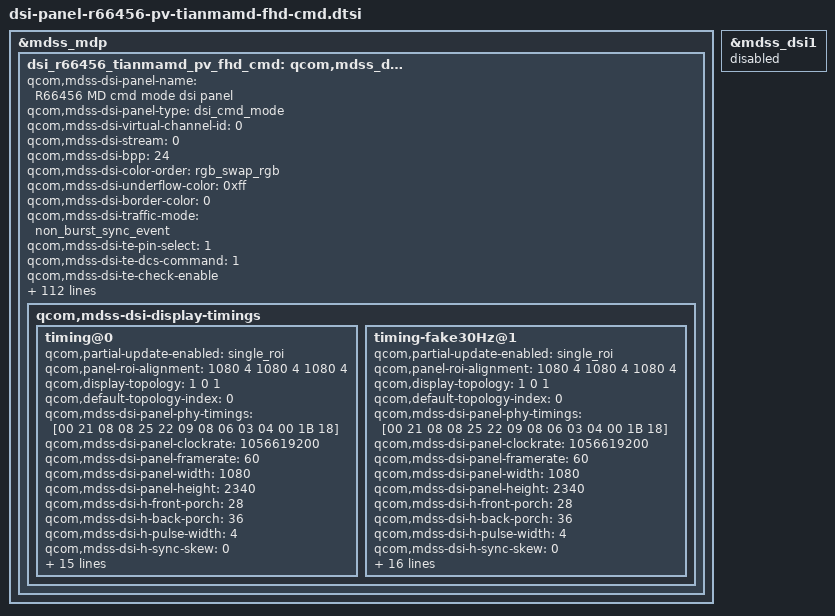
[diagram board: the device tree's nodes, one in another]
/* Copyright (c) 2014, Code Aurora Forum. All rights reserved.
 *
 * This program is free software; you can redistribute it and/or modify
 * it under the terms of the GNU General Public License version 2 and
 * only version 2 as published by the Free Software Foundation.
 *
 * This program is distributed in the hope that it will be useful,
 * but WITHOUT ANY WARRANTY; without even the implied warranty of
 * MERCHANTABILITY or FITNESS FOR A PARTICULAR PURPOSE.  See the
 * GNU General Public License for more details.
 */

&mdss_mdp {
    dsi_r66456_tianmamd_pv_fhd_cmd: qcom,mdss_dsi_r66456_tianmamd_pv_fhd_cmd {
		qcom,mdss-dsi-panel-name = "R66456 MD cmd mode dsi panel";
		qcom,mdss-dsi-panel-type = "dsi_cmd_mode";
		qcom,mdss-dsi-virtual-channel-id = <0>;
		qcom,mdss-dsi-stream = <0>;
		qcom,mdss-dsi-bpp = <24>;
		qcom,mdss-dsi-color-order = "rgb_swap_rgb";
		qcom,mdss-dsi-underflow-color = <0xff>;
		qcom,mdss-dsi-border-color = <0>;
		qcom,mdss-dsi-traffic-mode = "non_burst_sync_event";
		qcom,mdss-dsi-te-pin-select = <1>;
		qcom,mdss-dsi-te-dcs-command = <1>;
		qcom,mdss-dsi-te-check-enable;
		qcom,mdss-dsi-te-using-te-pin;
		qcom,mdss-dsi-lane-map = "lane_map_0123";
		qcom,mdss-dsi-bllp-eof-power-mode;
		qcom,mdss-dsi-bllp-power-mode;
		qcom,mdss-dsi-lane-0-state;
		qcom,mdss-dsi-lane-1-state;
		qcom,mdss-dsi-lane-2-state;
		qcom,mdss-dsi-lane-3-state;
		qcom,mdss-dsi-reset-sequence = <1 10>, <0 2>, <1 10>;
		qcom,mdss-dsi-dma-trigger = "trigger_sw";
		qcom,mdss-dsi-mdp-trigger = "none";
		qcom,mdss-dsi-wr-mem-start = <0x2c>;
		qcom,mdss-dsi-wr-mem-continue = <0x3c>;
		qcom,mdss-dsi-lp11-init;
		qcom,mdss-dsi-tx-eot-append;
		qcom,ulps-enabled;
		qcom,mdss-dsi-panel-hdr-enabled;
		qcom,mdss-dsi-panel-hdr-color-primaries = <14880 15935 32435 16555 14945 30910 7790 3415>;
		qcom,mdss-dsi-panel-peak-brightness = <5643000>;
		qcom,mdss-dsi-panel-blackness-level = <6134>;
		qcom,esd-check-enabled;
		qcom,mdss-dsi-panel-status-check-mode = "te_signal_check";

		lge,blmap = <
			0
			32 32 32 32 32 32 32 32 32 32 33 34 35 35 36 37 38 39 40 40
			41 42 43 44 45 46 46 47 48 49 50 51 51 52 53 54 57 59 62 65
			67 70 72 75 78 80 83 86 88 91 94 96 99 102 104 107 109 112 115 117
			120 126 131 137 143 148 154 160 165 171 177 182 188 194 199 205 211 216 222 228
			233 241 248 255 256 263 271 278 285 293 300 307 314 322 329 336 344 351 358 366
			373 380 387 395 402 409 417 424 434 443 453 462 472 481 491 500 510 519 529 538
			548 558 567 577 586 596 605 615 624 634 643 653 662 672 685 699 712 726 739 753
			766 776 789 802 816 829 843 856 870 883 897 910 923 937 950 964 977 991 1008 1023
			1026 1028 1030 1032 1034 1038 1042 1046 1055 1059 1060 1061 1075 1098 1131 1166 1203 1242 1283 1323
			1345 1361 1376 1393 1410 1427 1444 1461 1478 1495 1512 1529 1546 1563 1580 1597 1614 1631 1648 1665
			1682 1699 1716 1733 1750 1767 1784 1803 1822 1842 1861 1880 1899 1918 1938 1957 1976 1995 2014 2034
			2053 2072 2091 2110 2130 2149 2168 2187 2206 2226 2245 2264 2289 2315 2340 2366 2391 2416 2442 2467
			2493 2518 2543 2569 2594 2619 2645 2670 2696 2721 2746 2772 2797 2823 2848 2850 2851 2853 2855 2856
			2858 2860 2861 2863 2865 2866 2868 2870 2871 2873 2875 2877 2878 2880 2882 2883 2885 2887 2888 2890
			2892 2893 2895 2897 2898 2900 2904 2908 2911 2915 2919 2923 2926 2930 2938 2945 2953 2960 2968 2975
			2983 2990 2999 3009 3018 3028 3037 3047 3056 3066 3075 3084 3094 3103 3113 3122 3132 3141 3151 3160
			3171 3182 3192 3203 3214 3225 3235 3246 3257 3268 3278 3289 3300 3314 3328 3342 3355 3369 3383 3397
			3411 3425 3438 3452 3466 3480 3496 3511 3527 3542 3558 3573 3589 3605 3620 3636 3651 3667 3683 3698
			3714 3729 3745 3760 3776
		>;
		lge,blmap-ex = <
			0
			7 7 7 7 7 7 7 7 7 9 10 12 13 15 16 18 19 21 22 24
			25 27 28 30 31 33 34 36 37 39 40 42 43 45 46 48 50 53 55 58
			60 63 65 67 70 72 75 77 80 82 85 87 89 92 94 97 99 102 104 106
			109 111 114 116 119 121 124 126 128 131 133 136 138 141 143 151 159 167 175 183
			191 199 207 215 223 231 239 247 255 263 271 279 287 295 303 311 319 325 331 338
			344 350 356 362 368 375 381 387 393 399 405 412 418 424 430 435 440 445 450 455
			460 465 470 475 481 486 491 496 501 506 511 516 521 526 526 526 526 526 526 526
			534 541 549 556 564 571 579 587 594 602 609 617 625 632 640 647 655 662 670
		>;
		lge,blmap-ve = <
			0
			32 32 32 32 32 32 32 32 32 32 33 34 35 36 38 39 40 41 42 43
			44 45 47 48 49 50 51 52 53 54 55 57 58 59 60 61 64 68 71 74
			78 81 84 88 91 94 98 101 104 107 111 114 117 121 124 127 131 134 137 141
			144 151 159 166 173 181 188 195 203 210 217 225 232 239 247 254 261 269 276 283
			291 301 312 322 320 330 341 351 362 372 383 393 403 414 424 435 445 456 466 477
			487 497 508 518 529 539 550 560 573 586 599 612 625 638 650 663 676 689 702 715
			728 741 754 767 780 793 806 818 831 844 857 870 883 896 913 929 946 963 979 996
			1012 1025 1042 1059 1075 1092 1109 1125 1142 1159 1175 1192 1208 1225 1242 1258 1275 1292 1312 1330
			1349 1367 1385 1404 1422 1440 1459 1477 1495 1514 1532 1550 1569 1587 1605 1624 1642 1660 1679 1697
			1715 1734 1752 1775 1798 1821 1844 1867 1890 1913 1936 1959 1982 2005 2028 2051 2074 2097 2120 2143
			2166 2189 2212 2235 2258 2281 2304 2332 2360 2388 2416 2445 2473 2501 2529 2557 2585 2613 2641 2670
			2698 2726 2754 2782 2810 2838 2866 2895 2923 2951 2979 3007 3040 3074 3107 3141 3174 3208 3241 3274
			3308 3341 3375 3408 3442 3475 3509 3542 3575 3609 3642 3676 3709 3743 3776 3776 3776 3776 3776 3776
			3776 3776 3776 3776 3776 3776 3776 3776 3776 3776 3776 3776 3776 3776 3776 3776 3776 3776 3776 3776
			3776 3776 3776 3776 3776 3776 3776 3776 3776 3776 3776 3776 3776 3776 3776 3776 3776 3776 3776 3776
			3776 3776 3776 3776 3776 3776 3776 3776 3776 3776 3776 3776 3776 3776 3776 3776 3776 3776 3776 3776
			3776 3776 3776 3776 3776 3776 3776 3776 3776 3776 3776 3776 3776 3776 3776 3776 3776 3776 3776 3776
			3776 3776 3776 3776 3776 3776 3776 3776 3776 3776 3776 3776 3776 3776 3776 3776 3776 3776 3776 3776
			3776 3776 3776 3776 3776
		>;
		lge,blmap-hdr = <
			0
			32 32 32 32 32 32 32 32 32 32 33 34 35 36 37 38 39 40 41 42
			43 44 45 46 47 48 49 50 51 52 53 54 55 56 57 58 61 64 67 70
			74 77 80 83 86 89 92 95 99 102 105 108 111 114 117 120 124 127 130 133
			136 142 149 155 161 168 174 180 187 193 199 206 212 218 225 231 237 244 250 256
			263 272 281 290 288 297 306 315 324 333 342 351 360 369 378 387 397 406 415 424
			433 442 451 460 469 478 487 496 508 519 531 543 554 566 578 590 601 613 625 636
			648 660 671 683 695 706 718 730 742 753 765 777 788 800 816 832 848 864 880 896
			912 924 940 956 972 988 1004 1020 1036 1052 1068 1084 1100 1116 1132 1148 1164 1180 1200 1217
			1235 1252 1269 1287 1304 1321 1339 1356 1373 1391 1408 1425 1443 1460 1477 1495 1512 1529 1547 1564
			1581 1599 1616 1636 1656 1676 1696 1716 1736 1756 1776 1796 1816 1836 1856 1876 1896 1916 1936 1956
			1976 1996 2016 2036 2056 2076 2096 2121 2146 2171 2196 2221 2246 2270 2295 2320 2345 2370 2395 2420
			2445 2470 2495 2520 2545 2569 2594 2619 2644 2669 2694 2719 2750 2782 2813 2844 2876 2907 2938 2970
			3001 3032 3064 3095 3127 3158 3189 3221 3252 3283 3315 3346 3377 3409 3440 3441 3441 3442 3443 3443
			3444 3445 3445 3446 3446 3447 3448 3448 3449 3450 3450 3451 3452 3452 3453 3454 3454 3455 3455 3456
			3457 3457 3458 3459 3459 3460 3464 3468 3471 3475 3479 3483 3486 3490 3495 3500 3505 3510 3515 3520
			3525 3530 3533 3536 3538 3541 3544 3547 3549 3552 3555 3558 3561 3563 3566 3569 3572 3574 3577 3580
			3585 3589 3594 3598 3603 3608 3612 3617 3622 3626 3631 3635 3640 3645 3649 3654 3658 3663 3668 3672
			3677 3682 3686 3691 3695 3700 3704 3708 3712 3716 3720 3724 3728 3732 3736 3740 3744 3748 3752 3756
			3760 3764 3768 3772 3776
		>;
		qcom,mdss-pan-physical-width-dimension = <68>;
		qcom,mdss-pan-physical-height-dimension = <147>;

		qcom,mdss-dsi-t-clk-post = <0x18>;
		qcom,mdss-dsi-t-clk-pre = <0x1B>;

		lge,use-ambient;
		lge,aod-interface-data = "semi-partial", "semi-partial", "semi-partial";
		lge,mdss-dsi-nolp-command = [
			39 01 00 00 5A 00 03 51 00 00
			15 01 00 00 00 00 02 B0 00
			39 01 00 00 00 00 86 C1 90 42 04 38 00 3E 05 08 00 04 00 10 08 10 04 A9 8A 00 02 10 00 10 00 00 33 33 30 00 33 FF 00 00 00 00 20 00 00 00 C8 40 51 51 00 00 00 00 10 00 00 10 01 10 02 90 00 00 10 00 00 00 00 10 00 00 20 04 20 02 01 80 00 00 00 00 20 02 10 01 10 80 00 00 00 00 00 00 10 00 00 00 00 00 00 00 00 00 10 00 00 00 00 00 00 00 00 00 00 00 00 00 00 00 00 06 08 06 08 00 00 00 00 00 00 00 00 00 00 00 00 00 00 00 00
			39 01 00 00 00 00 3D C4 80 00 AA 00 00 00 00 00 00 00 00 01 00 00 00 1F 00 1F 00 00 00 00 00 00 00 00 0F 00 00 00 00 00 22 00 00 00 11 11 00 11 00 00 00 00 00 00 00 00 00 00 00 00 00 00 00 00 00 00 00 00
			15 01 00 00 00 00 02 B0 80
			39 01 00 00 00 00 87 E2 63 00 EE 00 FF 00 FF FF FF 00 FF 00 00 00 FF 00 00 00 FF FF FF FF 02 1C 08 3A 02 00 02 1C A7 DA 01 F4 07 DA 01 D8 07 F6 01 D8 A7 F6 01 BC 08 12 01 BC 08 3A 01 BC A8 3A 01 BC 08 62 01 D8 08 7E 01 D8 A8 7E 01 F4 08 9A 02 1C 08 9A 12 1C F7 DA 02 44 07 DA 02 60 07 F6 12 60 F7 F6 02 7C 08 12 02 7C 08 3A 12 7C F8 3A 02 7C 08 62 02 60 08 7E 12 60 F8 7E 02 44 08 9A 02 1C 08 9A 03 02 1C 08 3A 00 00 00 00 00
			15 01 00 00 00 00 02 B0 03
			15 01 00 00 32 00 02 88 00
		];
		lge,mdss-dsi-nolp-command-state = "dsi_lp_mode";

//		lge,mdss-dsi-aod-area-command = [
//			15 01 00 00 00 00 02 FE 00
//			39 01 00 00 00 00 05 30 00 00 04 37
//		];
//		lge,mdss-dsi-aod-area-command-state = "dsi_lp_mode";

		lge,mdss-dsi-lp2-command = [
			39 01 00 00 5A 00 03 51 00 00
			15 01 00 00 00 00 02 B0 00
			39 01 00 00 00 00 86 C1 D0 42 04 38 00 3F 05 48 00 15 55 10 08 10 04 99 89 00 02 10 00 10 00 00 33 33 30 00 33 FF 00 00 00 00 20 00 20 00 C8 40 51 51 00 00 00 00 10 00 00 10 01 10 02 90 00 00 10 00 00 00 00 10 00 00 20 04 20 02 01 80 00 00 00 00 20 02 10 01 10 80 00 00 00 00 00 00 10 00 00 00 00 00 00 00 00 00 10 00 00 00 00 00 00 00 00 00 00 00 00 00 00 00 00 06 08 06 08 00 00 00 00 00 00 00 00 00 00 00 00 00 00 00 00
			39 01 00 00 00 00 3D C4 80 00 AA 00 00 00 00 00 00 00 00 01 00 00 00 1F 00 1F 00 00 00 00 00 00 00 00 0F 00 00 00 00 00 22 00 00 00 11 11 00 11 00 00 98 31 03 00 00 00 00 00 00 00 00 00 00 00 00 00 00 00
			15 01 00 00 00 00 02 B0 80
			39 01 00 00 00 00 87 E2 63 00 D9 00 FF 00 FF FF FF 00 FF 00 00 00 FF 00 00 00 FF FF FF FF 02 1C 08 3A 02 00 02 1C A7 DA 01 F4 07 DA 01 D8 07 F6 01 D8 A7 F6 01 BC 08 12 01 BC 08 3A 01 BC A8 3A 01 BC 08 62 01 D8 08 7E 01 D8 A8 7E 01 F4 08 9A 02 1C 08 9A 12 1C F7 DA 02 44 07 DA 02 60 07 F6 12 60 F7 F6 02 7C 08 12 02 7C 08 3A 12 7C F8 3A 02 7C 08 62 02 60 08 7E 12 60 F8 7E 02 44 08 9A 02 1C 08 9A 03 02 1C 08 3A 00 00 00 00 00
			15 01 00 00 00 00 02 B0 03
			15 01 00 00 32 00 02 88 01
		];
		lge,mdss-dsi-lp2-command-state = "dsi_lp_mode";

		lge,use-vr-lp-mode;
		lge,mdss-dsi-vr-lp-mode-on-command = [
			15 01 00 00 00 00 02 B0 80
			39 01 00 00 00 00 04 DE 90 25 00
			15 01 00 00 00 00 02 B0 03

		];
		lge,mdss-dsi-vr-post-lp-mode-off-command = [
			15 01 00 00 00 00 02 B0 80
			39 01 00 00 00 00 04 DE 90 25 30
			15 01 00 00 00 00 02 B0 03
		];
		lge,mdss-dsi-vr-lp-command-state = "dsi_hs_mode";
		lge,blmap-vr = <
			0
			24 24 24 24 24 24 24 24 24 24 28 32 36 39 43 47 51 55 59 62
			66 70 74 78 82 86 89 93 97 101 105 109 112 116 120 124 128 132 136 139
			143 147 151 155 159 163 166 170 174 178 182 186 189 193 197 201 205 209 213 216
			220 224 228 232 236 239 243 247 251 255 259 263 266 270 274 278 282 286 289 293
			297 301 305 309 313 316 320 324 328 332 336 339 343 347 351 355 359 363 366 370
			374 378 382 386 390 393 397 401 405 409 413 416 420 424 428 432 436 440 443 447
			451 455 459 463 466 470 474 478
		>;

		lge,use-color-manager;
		lge,color-mode-cmds-dummy = [
			15 01 00 00 00 00 02 B0 00
			39 01 00 00 14 00 43 CE C1 1C F4 F0 FF EF 0A 0A 14 EF D3 EF DC E0 2B FE EB 03 00 FB F5 F5 E5 FF B6 97 E4 B6 97 3C 00 00 00 00 00 00 00 00 00 00 00 00 00 00 00 00 00 00 00 00 00 00 00 00 00 00 00 00 00 00 00 00 00 00 00 08
			15 01 00 00 00 00 02 B0 03
		];
		lge,color-mode-cmds-dummy-state = "dsi_hs_mode";
		lge,color-mode-set = [
			39 01 00 00 00 00 43 CE C1 1C F4 F0 FF EF 0A 0A 14 EF D3 EF DC E0 2B FE EB 03 00 FB F5 F5 E5 FF B6 97 E4 B6 97 3C 00 00 00 00 00 00 00 00 00 00 00 00 00 00 00 00 00 00 00 00 00 00 00 00 00 00 00 00 00 00 00 00 00 00 00 08
			39 01 00 00 00 00 43 CE C1 1C FC EF BC 0A 0D 31 D9 0B 29 D9 EC E6 D8 F1 F1 E4 E9 EE EA FD 13 FF 00 00 FC 19 00 FF 00 FF 00 67 F8 00 FF 00 00 FF 41 26 E6 FF 00 FF FF 74 F9 EC FF FF 00 FF FB 2D F6 FF FF FF 00 FD FC 00 FF 08
			39 01 00 00 00 00 43 CE C1 1C FC EF BB 00 D9 E3 09 EB E3 DC EE E5 F2 EE E3 F7 D8 E6 09 E9 DD FF 00 00 F0 47 31 FF 00 FF 00 00 FD 37 FF 00 00 FF 3F 26 E6 FF 00 FF FF 24 FD F3 FF FF 00 FF F5 4D E1 FF FF FF 00 FD FC 46 FF 08
			39 01 00 00 00 00 43 CE C1 1C FC EF BB E2 E8 ED E1 14 E0 DC F3 E8 DC F1 E0 D9 E0 E6 DC EF D7 FF 00 00 F0 47 31 FF 00 FF 00 8F F2 4F FF 00 00 FF 3F 26 E6 FF 00 FF FF 97 F3 E8 FF FF 00 FF F0 4C F6 FF FF FF 00 FD FC 59 FF 08
			39 01 00 00 00 00 43 CE C1 1C E2 EF FF EF 0A 0A 14 EF D3 EF DC E0 2B FE EB 03 00 FB F5 F5 E5 FF B6 97 E4 B6 97 3C 00 00 00 00 00 00 00 00 00 00 00 00 00 00 00 00 00 00 00 00 00 00 00 00 00 00 00 00 00 00 00 00 00 00 00 08
			39 01 00 00 00 00 43 CE C1 1C EB F4 F4 EF 0A 0A 14 EF D3 EF DC E0 2B FE EB 03 00 FB F5 F5 E5 FF B6 97 E4 B6 97 3C 00 00 00 00 00 00 00 00 00 00 00 00 00 00 00 00 00 00 00 00 00 00 00 00 00 00 00 00 00 00 00 00 00 00 00 08
			39 01 00 00 00 00 43 CE C1 1C F4 F0 FF EF 0A 0A 14 EF D3 EF DC E0 2B FE EB 03 00 FB F5 F5 E5 FF B6 97 E4 B6 97 3C 00 00 00 00 00 00 00 00 00 00 00 00 00 00 00 00 00 00 00 00 00 00 00 00 00 00 00 00 00 00 00 00 00 00 00 08
			39 01 00 00 00 00 43 CE C0 1C F8 FF F4 EF 0A 0A 14 EF D3 EF DC E0 2B FE EB 03 00 FB F5 F5 E5 FF B6 97 E6 B6 97 3C 00 00 00 00 00 00 00 00 00 00 00 00 00 00 00 00 00 00 00 00 00 00 00 00 00 00 00 00 00 00 00 00 00 00 00 08
		];
		lge,saturation-lut = [
			39 01 00 00 00 00 2A FF 00 00 D7 28 28 FF 00 FF 00 28 D7 28 FF 00 00 FF 28 28 D7 FF 00 FF FF 28 D7 D7 FF FF 00 FF D7 28 D7 FF FF FF 00 D7 D7 28 FF
			39 01 00 00 00 00 2A FF 00 00 EB 14 14 FF 00 FF 00 14 EB 14 FF 00 00 FF 14 14 EB FF 00 FF FF 14 EB EB FF FF 00 FF EB 14 EB FF FF FF 00 EB EB 14 FF
			39 01 00 00 00 00 2A FF B6 97 E6 B6 97 3C 00 00 00 00 00 00 00 00 00 00 00 00 00 00 00 00 00 00 00 00 00 00 00 00 00 00 00 00 00 00 00 00 00 00 00
			39 01 00 00 00 00 2A FF 80 80 FF 7B 7B 5D 80 FF 80 76 FF 76 5D 80 80 FF 76 76 FF 5D 80 FF FF 76 FF FF 5D FF 80 FF FF 76 FF 5D FF FF 80 FF FF 76 5D
			39 01 00 00 00 00 2A FF 80 80 FF 76 76 5D 80 FF 80 6C FF 6C 5D 80 80 FF 6C 6C FF 5D 80 FF FF 6C FF FF 5D FF 80 FF FF 6C FF 5D FF FF 80 FF FF 6C 5D
		];
		lge,custom-rgb-hue-lut = [
			39 01 00 00 00 00 12 EF 1E 0A 14 EF F1 0F DC E0 2B EA EB 03 00 E7 E1 F5 E5
			39 01 00 00 00 00 12 EF 14 0A 14 EF E2 01 DC E0 2B F4 EB 03 00 F1 EB F5 E5
			39 01 00 00 00 00 12 EF 0A 0A 14 EF D3 EF DC E0 2B FE EB 03 00 FB F5 F5 E5
			39 01 00 00 00 00 12 EF 0A 0A 14 EF D3 EF DC E0 2B FE EB 03 00 FB F5 F5 E5
			39 01 00 00 00 00 12 EF 0A 1E 32 EF D3 EF FA E0 2B FE D7 EE 00 FB F5 E1 E5
		];
		lge,mdss-dsi-sharpness-command = [
			15 01 00 00 00 00 02 B0 00
			39 01 00 00 00 00 05 DD 33 06 07 65
			15 01 00 00 00 00 02 B0 03
		];
		lge,mdss-dsi-sharpness-command-state = "dsi_hs_mode";
		lge,sharpness-lut = [
			39 01 00 00 00 00 05 DD 33 06 07 65
			39 01 00 00 00 00 05 DD 33 06 0E 65
			39 01 00 00 00 00 05 DD 33 06 15 65
			39 01 00 00 00 00 05 DD 33 06 1C 65
			39 01 00 00 00 00 05 DD 33 06 23 65
		];
		lge,rgb-lut = [
			39 01 00 00 00 00 03 F4 F0 FF
			39 01 00 00 00 00 03 F0 EC FB
			39 01 00 00 00 00 03 EC E8 F8
			39 01 00 00 00 00 03 E9 E4 F5
			39 01 00 00 00 00 03 E5 E1 F1
			39 01 00 00 00 00 03 E2 DD EE
			39 01 00 00 00 00 03 DE D9 EB
			39 01 00 00 00 00 03 DA D5 E7
			39 01 00 00 00 00 03 D7 D1 E4
			39 01 00 00 00 00 03 D3 CD E1
			39 01 00 00 00 00 03 D0 CA DD
			39 01 00 00 00 00 03 CC C6 DA
			39 01 00 00 00 00 03 C9 C2 D7
			39 01 00 00 00 00 03 C5 BE D3
			39 01 00 00 00 00 03 C1 BA D0
			39 01 00 00 00 00 03 BE B6 CC
			39 01 00 00 00 00 03 BA B2 C9
			39 01 00 00 00 00 03 B7 AF C6
			39 01 00 00 00 00 03 B3 AB C2
			39 01 00 00 00 00 03 AF A8 BF
			39 01 00 00 00 00 03 AC A5 BC
			39 01 00 00 00 00 03 A8 A2 B8
			39 01 00 00 00 00 03 A5 9F B5
			39 01 00 00 00 00 03 A1 9C B2
		];

		/* ACO */
		lge,use-ace-ctrl;
		lge,default-ace-mode = <1>;
		lge,mdss-dsi-ace-tune-command = [
			15 01 00 00 00 00 02 B0 00
			39 01 00 00 00 00 0C BC 33 25 CD 2B 19 06 03 C0 00 00 00
			15 01 00 00 00 00 02 B0 03
			15 01 00 00 14 00 02 55 00
			15 01 00 00 14 00 02 53 00
		];
		lge,mdss-dsi-ace-cmmand-state = "dsi_hs_mode";
		lge,ace-lut = [
			39 01 00 00 00 00 0C BC 33 25 FF 2B 19 22 53 C0 00 00 00
			39 01 00 00 00 00 0C BC 3B 45 CD 2B 19 59 03 C0 00 00 00
		];

		/* IRC */
		lge,use-irc-ctrl;
		lge,mdss-dsi-irc-command = [
			15 01 00 00 00 00 02 B0 80
			15 01 00 00 00 00 02 D3 01
			15 01 00 00 00 00 02 B0 03
		];
		lge,mdss-dsi-irc-command-state = "dsi_hs_mode";

		/* FP LHBM */
		lge,use-fp-lhbm;
		lge,mdss-dsi-fp-lhbm-command = [
			15 01 00 00 00 00 02 B0 80
			15 01 00 00 00 00 02 CC 11
			15 01 00 00 14 00 02 B0 03
		];
		lge,mdss-dsi-fp-lhbm-command-state = "dsi_hs_mode";

		lge,mdss-dsi-fp-lhbm-ready-command = [
			15 01 00 00 00 00 02 B0 00
			15 00 00 00 00 00 02 F1 25
			15 00 00 00 00 00 02 CF 09
			15 00 00 00 00 00 02 F1 4B
			39 00 00 00 00 00 03 CF 00 00
			15 00 00 00 00 00 02 F1 73
			39 00 00 00 00 00 03 CF 00 00
			15 00 00 00 00 00 02 F1 D7
			39 00 00 00 00 00 03 CF 0F 85
			15 00 00 00 00 00 02 F1 06
			39 01 00 00 00 00 0E CF 00 00 00 00 00 00 00 00 00 00 00 00 00
			15 01 00 00 00 00 02 B0 80
			15 00 00 00 00 00 02 F1 04
			39 00 00 00 00 00 09 D3 00 60 C0 C0 C0 C0 C0 E0
			15 00 00 00 00 00 02 F1 38
			39 01 00 00 00 00 59 D3 E0 FF FF FF F6 F6 F9 FF F1 F1 F5 FC F1 F1 F5 FC FF FF FF FF FC FC FC FD F8 F9 F9 F8 F6 F7 F7 F6 B7 FF FF 75 77 77 78 78 78 79 7A 7B 7C 7C 7C 7D 7D 7E 7F 80 75 77 77 78 78 78 79 7A 7B 7C 7C 7C 7D 7D 7E 7F 80 75 77 77 78 78 78 79 7A 7B 7C 7C 7C 7D 7D 7E 7F 80 1C EC
			15 01 00 00 14 00 02 B0 03
		];
		lge,mdss-dsi-fp-lhbm-ready-command-state = "dsi_hs_mode";

		lge,mdss-dsi-fp-lhbm-exit-command = [
			15 01 00 00 00 00 02 B0 00
			15 00 00 00 00 00 02 F1 D7
			39 01 00 00 00 00 03 CF 0B 33
			15 00 00 00 00 00 02 F1 25
			15 00 00 00 00 00 02 CF 08
			15 00 00 00 00 00 02 F1 06
			39 01 00 00 14 00 0E CF 0D 00 58 00 E8 01 DE 04 AA 0B 32 0F FE
		];
		lge,mdss-dsi-fp-lhbm-exit-command-state = "dsi_hs_mode";
		lge,mdss-dsi-fp-lhbm-exit-post-command = [
			15 00 00 00 00 00 02 F1 4B
			39 00 00 00 00 00 03 CF 03 99
			15 00 00 00 00 00 02 F1 73
			39 00 00 00 00 00 03 CF 03 99
			15 01 00 00 00 00 02 B0 80
			15 00 00 00 00 00 02 F1 04
			39 00 00 00 00 00 09 D3 FF FF FF FF FF FF FF FF
			15 00 00 00 00 00 02 F1 38
			39 01 00 00 00 00 59 D3 EA FB FB FB F5 FB FB F5 F0 F8 F8 F0 ED F0 F0 ED FF FF FF FF FE FE FE FE FD FD FD FD FC FC FC FC D6 FF C4 5B 5E 61 64 67 6A 6D 70 73 76 79 7B 7C 7E 7F 7F 80 5B 5E 61 64 67 6A 6D 70 73 76 79 7B 7C 7E 7F 7F 80 5B 5E 61 64 67 6A 6D 70 73 76 79 7B 7C 7E 7F 7F 80 17 BB
			15 01 00 00 14 00 02 B0 03
		];
		lge,mdss-dsi-fp-lhbm-exit-post-command-state = "dsi_hs_mode";

		lge,mdss-dsi-fp-lhbm-irc-command = [
			15 01 00 00 00 00 02 B0 80
			15 00 00 00 00 00 02 F1 04
			39 00 00 00 00 00 09 D3 00 60 C0 C0 C0 C0 C0 E0
			15 00 00 00 00 00 02 F1 38
			39 01 00 00 00 00 59 D3 E0 FF FF FF F6 F6 F9 FF F1 F1 F5 FC F1 F1 F5 FC FF FF FF FF FC FC FC FD F8 F9 F9 F8 F6 F7 F7 F6 B7 FF FF 75 77 77 78 78 78 79 7A 7B 7C 7C 7C 7D 7D 7E 7F 80 75 77 77 78 78 78 79 7A 7B 7C 7C 7C 7D 7D 7E 7F 80 75 77 77 78 78 78 79 7A 7B 7C 7C 7C 7D 7D 7E 7F 80 1C EC
			15 01 00 00 14 00 02 B0 03
		];
		lge,mdss-dsi-fp-lhbm-irc-command-state = "dsi_hs_mode";
		lge,mdss-dsi-fp-norm-irc-command = [
			15 01 00 00 00 00 02 B0 80
			15 00 00 00 00 00 02 F1 04
			39 00 00 00 00 00 09 D3 FF FF FF FF FF FF FF FF
			15 00 00 00 00 00 02 F1 38
			39 01 00 00 00 00 59 D3 EA FB FB FB F5 FB FB F5 F0 F8 F8 F0 ED F0 F0 ED FF FF FF FF FE FE FE FE FD FD FD FD FC FC FC FC D6 FF C4 5B 5E 61 64 67 6A 6D 70 73 76 79 7B 7C 7E 7F 7F 80 5B 5E 61 64 67 6A 6D 70 73 76 79 7B 7C 7E 7F 7F 80 5B 5E 61 64 67 6A 6D 70 73 76 79 7B 7C 7E 7F 7F 80 17 BB
			15 01 00 00 14 00 02 B0 03
		];
		lge,mdss-dsi-fp-norm-irc-command-state = "dsi_hs_mode";

		/* tc Perf */
		lge,use-tc-perf;
		lge,mdss-dsi-tc-perf-command = [
			15 01 00 00 00 00 02 B0 00
			39 01 00 00 00 00 F2 CF 0F 00 00 00 00 00 00 00 0C 00 53 01 3B 02 11 0A 56 0E C4 04 04 04 04 04 04 04 04 04 05 05 06 06 07 07 07 07 08 08 09 00 FF 00 FF 00 FF 00 FF 00 FF 00 FF 00 B8 00 B8 00 B8 00 B8 00 B8 00 B8 00 B8 00 B8 00 B7 03 99 03 99 03 99 03 99 03 99 03 FF 03 FF 03 FF 03 FF 03 FF 03 FF 00 B8 00 B8 00 B8 00 B8 00 B8 00 B8 00 B8 00 B8 00 B8 03 99 03 99 03 99 03 99 03 99 01 2F 01 2F 01 2F 01 2F 01 2F 01 2F 01 2F 01 2F 01 2F 01 2F 01 2F 01 2F 01 2F 01 2F 01 2F 01 2F 01 2F 01 2F 01 2F 01 2F 26 26 26 26 26 26 26 26 26 26 26 26 26 26 26 26 26 26 26 26 00 00 0F FF 0F FF 0F FF 0F FF 0F FF 00 00 00 41 00 41 01 BC 01 BC 06 A8 06 A8 0F 85 0F 85 0F 85 0F 85 0F 85 0F 85 0F 85 2B 2B 2B 2B 2B 2B 2B 2B 2B 2B 2B 2B 2B 2B 2B 2B 2B 2B 2B 2B 19 19
			15 01 00 00 00 00 02 B0 03
		];
		lge,mdss-dsi-tc-perf-command-state = "dsi_hs_mode";

		qcom,mdss-dsi-display-timings {
			timing@0{
				qcom,partial-update-enabled = "single_roi";
				qcom,panel-roi-alignment = <1080 4 1080 4 1080 4>;
				qcom,display-topology = <1 0 1>;
				qcom,default-topology-index = <0>;
				qcom,mdss-dsi-panel-phy-timings = [00 21 08 08 25 22 09 08 06 03 04 00 1B 18];
				qcom,mdss-dsi-panel-clockrate = <1056619200>;
				qcom,mdss-dsi-panel-framerate = <60>;
				qcom,mdss-dsi-panel-width = <1080>;
				qcom,mdss-dsi-panel-height = <2340>;
				qcom,mdss-dsi-h-front-porch = <28>;
				qcom,mdss-dsi-h-back-porch = <36>;
				qcom,mdss-dsi-h-pulse-width = <4>;
				qcom,mdss-dsi-h-sync-skew = <0>;
				qcom,mdss-dsi-v-back-porch = <4>;
				qcom,mdss-dsi-v-front-porch = <12>;
				qcom,mdss-dsi-v-pulse-width = <4>;
				qcom,mdss-dsi-h-left-border = <0>;
				qcom,mdss-dsi-h-right-border = <0>;
				qcom,mdss-dsi-v-top-border = <0>;
				qcom,mdss-dsi-v-bottom-border = <0>;
				qcom,mdss-mdp-transfer-time-us = <15200>;

				qcom,mdss-dsi-on-command = [
					15 01 00 00 00 00 02 B0 00
					39 01 00 00 00 00 3A BB 59 C8 C8 C8 C8 C8 C8 C8 C8 C8 4A 48 46 44 42 40 3E 3C 3A 00 00 FF FF FF FF FF FF FF FF FF FF FF FF FF FF FF FF FF FF 00 00 42 04 69 5A 69 5A 20 0F FD 0F FF 0F FF 0F FF 14
					39 01 00 00 00 00 43 CE C1 1C F4 F0 FF EF 0A 0A 14 EF D3 EF DC E0 2B FE EB 03 00 FB F5 F5 E5 FF B6 97 E4 B6 97 3C 00 00 00 00 00 00 00 00 00 00 00 00 00 00 00 00 00 00 00 00 00 00 00 00 00 00 00 00 00 00 00 00 00 00 00 08
					39 01 00 00 00 00 0A D1 09 30 02 1C 26 1D 4E 1E 00
					15 01 00 00 00 00 02 B0 80
					39 01 00 00 00 00 95 D3 01 FF FF FF FF FF FF FF FF FF FF FF FF 00 03 0C 1E 38 5B 89 C0 FF 00 03 0C 1E 38 5B 89 C0 FF 00 03 0C 1E 38 5B 89 C0 FF FF FF FF FF FF FF FF FF FF FF FF FF FF FF FF FF EA FB FB FB F5 FB FB F5 F0 F8 F8 F0 ED F0 F0 ED FF FF FF FF FE FE FE FE FD FD FD FD FC FC FC FC D6 FF C4 5B 5E 61 64 67 6A 6D 70 73 76 79 7B 7C 7E 7F 7F 80 5B 5E 61 64 67 6A 6D 70 73 76 79 7B 7C 7E 7F 7F 80 5B 5E 61 64 67 6A 6D 70 73 76 79 7B 7C 7E 7F 7F 80 17 BB 02 D0 00 08
					39 01 00 00 00 00 87 E2 63 00 EE 00 FF 00 FF FF FF 00 FF 00 00 00 FF 00 00 00 FF FF FF FF 02 1C 08 3A 02 00 02 1C A7 DA 01 F4 07 DA 01 D8 07 F6 01 D8 A7 F6 01 BC 08 12 01 BC 08 3A 01 BC A8 3A 01 BC 08 62 01 D8 08 7E 01 D8 A8 7E 01 F4 08 9A 02 1C 08 9A 12 1C F7 DA 02 44 07 DA 02 60 07 F6 12 60 F7 F6 02 7C 08 12 02 7C 08 3A 12 7C F8 3A 02 7C 08 62 02 60 08 7E 12 60 F8 7E 02 44 08 9A 02 1C 08 9A 03 02 1C 08 3A 00 00 00 00 00
					39 01 00 00 00 00 0B E1 01 00 21 1A 0F FF 04 04 42 02
					39 01 00 00 00 00 1F B6 42 34 01 05 00 00 09 23 07 30 09 23 02 1C 01 F4 00 00 00 00 01 0E 01 0E 00 00 02 3B 58 0C
					39 01 00 00 00 00 5C DF 57 50 00 00 00 00 00 10 2E 32 28 A0 AA AA A0 AA AA A0 00 00 00 00 03 84 00 09 00 6A 35 3E 00 00 51 50 00 00 60 07 60 07 00 60 01 00 00 00 00 00 00 00 00 00 00 00 04 30 00 00 00 00 00 00 00 00 4C 00 01 00 00 00 00 00 00 00 00 00 00 00 00 00 00 00 00 00 AA AA 0A AA AA 0A 0B
					15 01 00 00 00 00 02 E6 00
					15 01 00 00 00 00 02 B0 03
					15 01 00 00 00 00 02 35 00
					39 01 00 00 00 00 05 2A 00 00 04 37
					39 01 00 00 00 00 05 2B 00 00 09 23
					05 01 00 00 00 00 01 29
					05 01 00 00 96 00 01 11
				];
				qcom,mdss-dsi-on-command-state = "dsi_lp_mode";

				qcom,mdss-dsi-off-command = [
					15 01 00 00 00 00 02 B0 03
					39 01 00 00 5A 00 03 51 00 00
					05 01 00 00 00 00 01 28
					05 01 00 00 96 00 01 10
				];
				qcom,mdss-dsi-off-command-state = "dsi_lp_mode";
				qcom,mdss-dsi-h-sync-pulse = <0>;
			};
			timing-fake30Hz@1{
				qcom,partial-update-enabled = "single_roi";
				qcom,panel-roi-alignment = <1080 4 1080 4 1080 4>;
				qcom,display-topology = <1 0 1>;
				qcom,default-topology-index = <0>;
				qcom,mdss-dsi-panel-phy-timings = [00 21 08 08 25 22 09 08 06 03 04 00 1B 18];
				qcom,mdss-dsi-panel-clockrate = <1056619200>;
				qcom,mdss-dsi-panel-framerate = <60>;
				qcom,mdss-dsi-panel-width = <1080>;
				qcom,mdss-dsi-panel-height = <2340>;
				qcom,mdss-dsi-h-front-porch = <28>;
				qcom,mdss-dsi-h-back-porch = <36>;
				qcom,mdss-dsi-h-pulse-width = <4>;
				qcom,mdss-dsi-h-sync-skew = <0>;
				qcom,mdss-dsi-v-back-porch = <4>;
				qcom,mdss-dsi-v-front-porch = <12>;
				qcom,mdss-dsi-v-pulse-width = <4>;
				qcom,mdss-dsi-h-left-border = <0>;
				qcom,mdss-dsi-h-right-border = <0>;
				qcom,mdss-dsi-v-top-border = <0>;
				qcom,mdss-dsi-v-bottom-border = <0>;
				qcom,mdss-mdp-transfer-time-us = <15200>;
				lge,mdss-dsi-panel-framerate-div = <2>;

				qcom,mdss-dsi-on-command = [
					15 01 00 00 00 00 02 B0 00
					39 01 00 00 00 00 3A BB 59 C8 C8 C8 C8 C8 C8 C8 C8 C8 4A 48 46 44 42 40 3E 3C 3A 00 00 FF FF FF FF FF FF FF FF FF FF FF FF FF FF FF FF FF FF 00 00 42 04 69 5A 69 5A 20 0F FD 0F FF 0F FF 0F FF 14
					39 01 00 00 00 00 43 CE C1 1C F4 F0 FF EF 0A 0A 14 EF D3 EF DC E0 2B FE EB 03 00 FB F5 F5 E5 FF B6 97 E4 B6 97 3C 00 00 00 00 00 00 00 00 00 00 00 00 00 00 00 00 00 00 00 00 00 00 00 00 00 00 00 00 00 00 00 00 00 00 00 08
					39 01 00 00 00 00 0A D1 09 30 02 1C 26 1D 4E 1E 00
					15 01 00 00 00 00 02 B0 80
					39 01 00 00 00 00 95 D3 01 FF FF FF FF FF FF FF FF FF FF FF FF 00 03 0C 1E 38 5B 89 C0 FF 00 03 0C 1E 38 5B 89 C0 FF 00 03 0C 1E 38 5B 89 C0 FF FF FF FF FF FF FF FF FF FF FF FF FF FF FF FF FF EA FB FB FB F5 FB FB F5 F0 F8 F8 F0 ED F0 F0 ED FF FF FF FF FE FE FE FE FD FD FD FD FC FC FC FC D6 FF C4 5B 5E 61 64 67 6A 6D 70 73 76 79 7B 7C 7E 7F 7F 80 5B 5E 61 64 67 6A 6D 70 73 76 79 7B 7C 7E 7F 7F 80 5B 5E 61 64 67 6A 6D 70 73 76 79 7B 7C 7E 7F 7F 80 17 BB 02 D0 00 08
					39 01 00 00 00 00 87 E2 63 00 EE 00 FF 00 FF FF FF 00 FF 00 00 00 FF 00 00 00 FF FF FF FF 02 1C 08 3A 02 00 02 1C A7 DA 01 F4 07 DA 01 D8 07 F6 01 D8 A7 F6 01 BC 08 12 01 BC 08 3A 01 BC A8 3A 01 BC 08 62 01 D8 08 7E 01 D8 A8 7E 01 F4 08 9A 02 1C 08 9A 12 1C F7 DA 02 44 07 DA 02 60 07 F6 12 60 F7 F6 02 7C 08 12 02 7C 08 3A 12 7C F8 3A 02 7C 08 62 02 60 08 7E 12 60 F8 7E 02 44 08 9A 02 1C 08 9A 03 02 1C 08 3A 00 00 00 00 00
					39 01 00 00 00 00 0B E1 01 00 21 1A 0F FF 04 04 42 02
					39 01 00 00 00 00 1F B6 42 34 01 05 00 00 09 23 07 30 09 23 02 1C 01 F4 00 00 00 00 01 0E 01 0E 00 00 02 3B 58 0C
					39 01 00 00 00 00 5C DF 57 50 00 00 00 00 00 10 2E 32 28 A0 AA AA A0 AA AA A0 00 00 00 00 03 84 00 09 00 6A 35 3E 00 00 51 50 00 00 60 07 60 07 00 60 01 00 00 00 00 00 00 00 00 00 00 00 04 30 00 00 00 00 00 00 00 00 4C 00 01 00 00 00 00 00 00 00 00 00 00 00 00 00 00 00 00 00 AA AA 0A AA AA 0A 0B
					15 01 00 00 00 00 02 E6 00
					15 01 00 00 00 00 02 B0 03
					15 01 00 00 00 00 02 35 00
					39 01 00 00 00 00 05 2A 00 00 04 37
					39 01 00 00 00 00 05 2B 00 00 09 23
					05 01 00 00 00 00 01 29
					05 01 00 00 96 00 01 11
				];
				qcom,mdss-dsi-on-command-state = "dsi_lp_mode";

				qcom,mdss-dsi-off-command = [
					15 01 00 00 00 00 02 B0 03
					39 01 00 00 5A 00 03 51 00 00
					05 01 00 00 00 00 01 28
					05 01 00 00 96 00 01 10
				];
				qcom,mdss-dsi-off-command-state = "dsi_lp_mode";
				qcom,mdss-dsi-h-sync-pulse = <0>;
			};
		};
	};
};
/*
&spmi_bus {
	qcom,pmi8998@3 {
		labibb: qpnp-labibb-regulator {
			status = "disabled";
		};
	};
};
*/
&mdss_dsi1 {
	status = "disabled";
};
